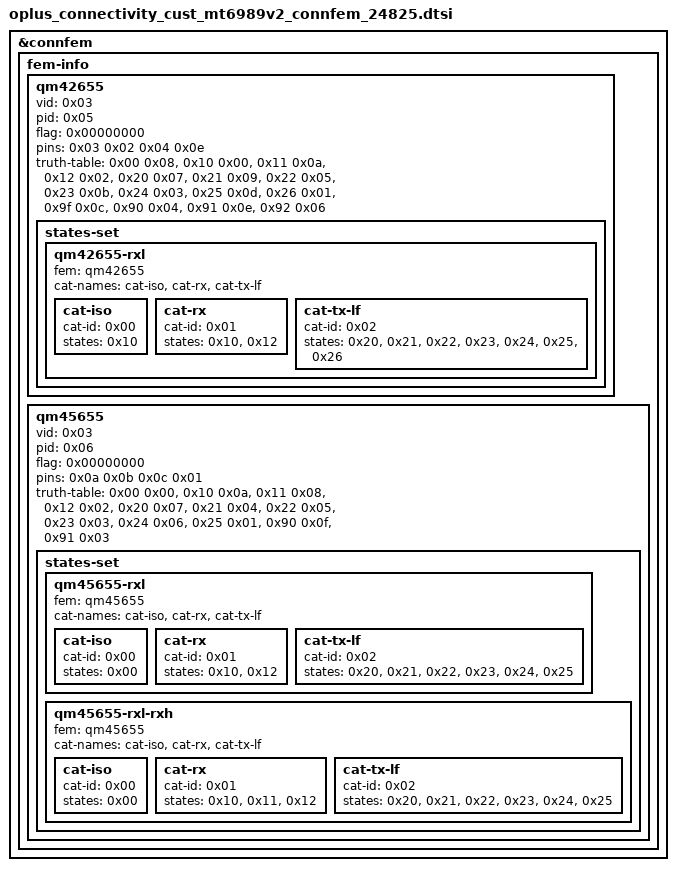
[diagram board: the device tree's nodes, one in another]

&connfem {
	fem-info {
		qm42655 {
			vid = <0x03>;
			pid = <0x05>;
			flag = <0x00000000>;

			/* [0] 0x03: SEL1/PAEN
			 * [1] 0x02: SEL2/LNAEN
			 * [2] 0x04: SEL3/BTEN
			 * [3] 0x0e: SEL4
			 */
			pins = <0x03 0x02 0x04 0x0e>;

			truth-table =
				<0x00 0x08>,	/* ISO - ISO */
				<0x10 0x00>,	/* BYP - WIFI_RX_BYP */
				<0x11 0x0a>,	/* RxL - WIFI_RX_G0 */
				<0x12 0x02>,	/* RxH - WIFI_RX_G1 */
				<0x20 0x07>,	/* TxL - WIFI_TX_LF_G0 */
				<0x21 0x09>,	/* TxML - WIFI_TX_LF_G1 */
				<0x22 0x05>,	/* TxM - WIFI_TX_LF_G2 */
				<0x23 0x0b>,	/* TxMH - WIFI_TX_LF_G3 */
				<0x24 0x03>,	/* TxHE2 - WIFI_TX_LF_G4 */
				<0x25 0x0d>,	/* TxHE1 - WIFI_TX_LF_G5 */
				<0x26 0x01>,	/* TxH - WIFI_TX_LF_G6 */
				<0x9f 0x0c>,	/* BTBYP - BT_TX_BYP */
				<0x90 0x04>,	/* BTL - BT_TX_G0 */
				<0x91 0x0e>,	/* BTM - BT_TX_G1 */
				<0x92 0x06>;	/* BTH - BT_TX_G2 */

			states-set {
				qm42655-rxl {
					fem = <&qm42655>;
					cat-names = "cat-iso", "cat-rx", "cat-tx-lf";
					cat-iso {
						cat-id = <0x00>;
						states =
							<0x10>;	/* BYP */
					};
					cat-rx {
						cat-id = <0x01>;
						states =
							<0x10>,	/* BYP */
							<0x12>;	/* RxH */
					};
					cat-tx-lf {
						cat-id = <0x02>;
						states =
							<0x20>,	/* TxL */
							<0x21>,	/* TxML */
							<0x22>,	/* TxM */
							<0x23>,	/* TxMH */
							<0x24>,	/* TxHE2 */
							<0x25>,	/* TxHE1 */
							<0x26>;	/* TxH */
					};
				};
			};
		};

		qm45655 {
			vid = <0x03>;
			pid = <0x06>;
			flag = <0x00000000>;

			/* [0] 0x0a: SEL1/PAEN
			 * [1] 0x0b: SEL2/LNAEN
			 * [2] 0x0c: SEL3
			 * [3] 0x01: SEL4
			 */
			pins = <0x0a 0x0b 0x0c 0x01>;

			truth-table =
				<0x00 0x00>,	/* ISO - ISO */
				<0x10 0x0a>,	/* BYP - WIFI_RX_BYP */
				<0x11 0x08>,	/* RxL - WIFI_RX_G0 */
				<0x12 0x02>,	/* RxH - WIFI_RX_G1 */
				<0x20 0x07>,	/* TxL - WIFI_TX_LF_G0 */
				<0x21 0x04>,	/* TxML - WIFI_TX_LF_G1 */
				<0x22 0x05>,	/* TxM - WIFI_TX_LF_G2 */
				<0x23 0x03>,	/* TxMH - WIFI_TX_LF_G3 */
				<0x24 0x06>,	/* TxHE - WIFI_TX_LF_G4 */
				<0x25 0x01>,	/* TxH - WIFI_TX_LF_G5 */
				<0x90 0x0f>,	/* BTL - BT_TX_G0 */
				<0x91 0x03>;	/* BTH - BT_TX_G1 */

			states-set {
				qm45655-rxl {
					fem = <&qm45655>;
					cat-names = "cat-iso", "cat-rx", "cat-tx-lf";
					cat-iso {
						cat-id = <0x00>;
						states =
							<0x00>;	/* ISO */
					};
					cat-rx {
						cat-id = <0x01>;
						states =
							<0x10>,	/* BYP */
							<0x12>;	/* RxH */
					};
					cat-tx-lf {
						cat-id = <0x02>;
						states =
							<0x20>,	/* TxL */
							<0x21>,	/* TxML */
							<0x22>,	/* TxM */
							<0x23>,	/* TxMH */
							<0x24>,	/* TxHE */
							<0x25>;	/* TxH */
					};
				};

				qm45655-rxl-rxh {
					fem = <&qm45655>;
					cat-names = "cat-iso", "cat-rx", "cat-tx-lf";
					cat-iso {
						cat-id = <0x00>;
						states =
							<0x00>;	/* ISO */
					};
					cat-rx {
						cat-id = <0x01>;
						states =
							<0x10>,	/* BYP */
							<0x11>,	/* RxL */
							<0x12>; /* RxH */
					};
					cat-tx-lf {
						cat-id = <0x02>;
						states =
							<0x20>,	/* TxL */
							<0x21>,	/* TxML */
							<0x22>,	/* TxM */
							<0x23>,	/* TxMH */
							<0x24>,	/* TxHE */
							<0x25>;	/* TxH */
					};
				};
			};
		};
	};
};
